# CY8C4245AXI_483 register map
File version: 0.1
PSoC 4200
Registers are 32-bit, read-write, no defined reset value unless marked. A register's access mark holds for its fields unless they carry their own. Offsets are from the block's base; lines under a group give offsets from that group; [hi:lo] are bit positions; {n}, {i} and the like mark numbered series; 'fields as' and 'values as' point back to an identical list; <NAME> marks a mode.

## Memory map
0x00000000 PC_Uart — Serial Communication Block
0x00000000 Rot2
0x00000000 CapSense_IDAC1 — IDAC
0x00000000 CapSense_IDAC2 — IDAC
0x00000000 ResetTimer
0x00000000 Rot1
0x00000000 ESP — Serial Communication Block
0x400F0061 RotSWReg
0x400F0073 StripLights_StringSel

## Rot2
Base 0x00000000
0x40050148 COUNTER — Current counter value
0x4005014C CC — Compare / capture value
0x40050150 CC_BUF — Compare / capture buffer value
0x40050154 PERIOD — Period value
0x40050158 PERIOD_BUF — Period buffer value

## CapSense_IDAC1 — IDAC
Base 0x00000000
Same registers: CapSense_IDAC2 0x00000000
0x40080004 CSD_IDAC_POLARITY
0x40080008 CSD_IDAC
0x4008FF00 CSD_TRIM1 — CSD IDAC TRIM1
0x4008FF04 CSD_TRIM2 — CSD IDAC TRIM2

## RotSWReg
Base 0x400F0061
0x00 RotSWReg_STATUS_REG 8-bit
0x20 RotSWReg_MASK_REG 8-bit
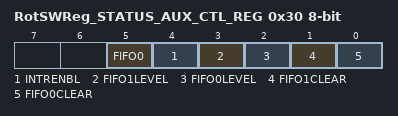
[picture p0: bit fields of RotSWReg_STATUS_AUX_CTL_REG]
0x30 RotSWReg_STATUS_AUX_CTL_REG 8-bit
  [5] FIFO0 — FIFO0 clear
    1=ENABLED (Enable counter); 0=DISABLED (Disable counter)
  [4] INTRENBL — Enables or disables the Interrupt
    1=ENABLED (Interrupt enabled); 0=DISABLED (Interrupt disabled)
  [3] FIFO1LEVEL — FIFO level
    1=ENABLED (FIFO LVL: input mode: FIFO at least 1/2 empty; output mode: FIFO at least 1/2 full); 0=DISABLED (FIFO LVL: input mode: FIFO not full; output mode: FIFO not empty)
  [2] FIFO0LEVEL — FIFO level
    values as FIFO1LEVEL
  [1] FIFO1CLEAR — FIFO clear
    1=ENABLED (Clear FIFO state); 0=DISABLED (Normal FIFO operation)
  [0] FIFO0CLEAR — FIFO clear
    values as FIFO1CLEAR

## StripLights_StringSel
Base 0x400F0073
0x00 StripLights_StringSel_CONTROL_REG 8-bit

## ResetTimer
Base 0x00000000
0x40050188 COUNTER — Current counter value
0x4005018C CC — Compare / capture value
0x40050190 CC_BUF — Compare / capture buffer value
0x40050194 PERIOD — Period value
0x40050198 PERIOD_BUF — Period buffer value

## Rot1
Base 0x00000000
0x40050108 COUNTER — Current counter value
0x4005010C CC — Compare / capture value
0x40050110 CC_BUF — Compare / capture buffer value
0x40050114 PERIOD — Period value
0x40050118 PERIOD_BUF — Period buffer value
